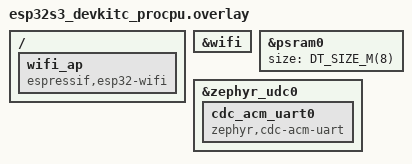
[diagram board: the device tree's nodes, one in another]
&wifi {
	status = "okay";
};

/ {
	wifi_ap: wifi_ap {
		compatible = "espressif,esp32-wifi";
		status = "okay";
	};
};

&psram0 {
	size = <DT_SIZE_M(8)>;
};

/* CDC-ACM UART node required by CONFIG_USB_CDC_ACM */
&zephyr_udc0 {
	cdc_acm_uart0: cdc_acm_uart0 {
		compatible = "zephyr,cdc-acm-uart";
	};
};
